VERSION ""

NS_ :

BS_:
BU_: POD STARC VCU

BO_ 5 HEARTBEAT_VCU: 1 VCU
  SG_ HEARTBEAT_CMD : 0|8@0- (1,0) [0|255] "" POD

BO_ 109 FRONT_STEER_CMD: 8 POD,STARC
  SG_ FRONT_STEER_ANGLE : 0|16@0- (1,0) [-150|150] "degrees" VCU
  SG_ REAR_STEER_ANGLE : 16|16@0- (1,0) [-150|150] "degrees" VCU
  SG_ STEER_RATE : 32|8@0+ (1,0) [-128|128] "rad/s" VCU
  SG_ CTRL_REQUEST : 40|4@0- (1,0) [0|8] "" VCU
  SG_ CTRL_PRIORITY : 44|4@0- (1,0) [0|8] "" VCU

BO_ 110 STEERING_STATUS: 8 VCU
  SG_ FRONT_STEER_ANGLE : 0|16@0- (1,0) [-150|150] "degrees" POD,STARC
  SG_ REAR_STEER_ANGLE : 16|16@0- (1,0) [-150|150] "degrees" POD,STARC
  SG_ MOTOR_TEMP : 32|8@0- (1,0) [0|110] "celcius" POD,STARC
  SG_ MOTOR_CURRENT : 40|8@0- (1,0) [0|100] "Amperes" POD,STARC
  SG_ STEER_ANGLE_ERROR : 48|8@0- (1,0) [-150|150] "degrees" POD,STARC
  SG_ STEER_ANGLE_STATUS : 56|4@0- (1,0) [0|8] "" POD,STARC

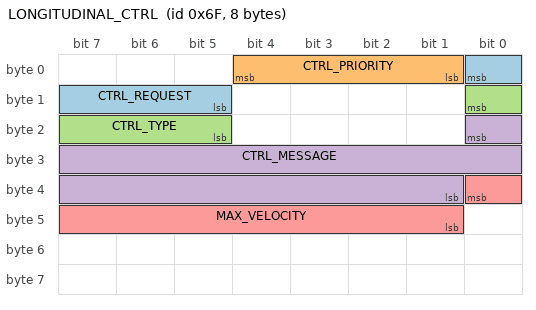
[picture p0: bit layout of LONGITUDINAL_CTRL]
BO_ 111 LONGITUDINAL_CTRL: 8 POD,STARC
  SG_ CTRL_REQUEST : 0|4@0- (1,0) [0|8] "" VCU
  SG_ CTRL_PRIORITY : 4|4@0- (1,0) [0|8] "" VCU
  SG_ CTRL_TYPE : 8|4@0- (1,0) [0|8] "" VCU
  SG_ CTRL_MESSAGE : 16|16@0- (1,0) [0|65536] "" VCU
  SG_ MAX_VELOCITY : 32|8@0- (1,0) [0|255] "" VCU

BO_ 112 TORQUE_VECTORS: 8 POD
  SG_ F_L_CTRL_MSG : 0|16@0- (1,0) [0|65536] "" VCU
  SG_ R_L_CTRL_MSG : 16|16@0- (1,0) [0|65536] "" VCU
  SG_ F_R_CTRL_MSG : 32|16@0- (1,0) [0|65536] "" VCU
  SG_ R_R_CTRL_MSG : 48|16@0- (1,0) [0|65536] "" VCU

BO_ 113 LONGITUDIANL STATUS: 8 VCU
  SG_ WHEEL_POS_CTR : 0|12@0- (1,0) [0|4096] "" VCU
  SG_ WHEEL_VELOCITY : 12|10@0+ (1,0) [-512|512] "rad/s" VCU
  SG_ STATOR_TEMP : 22|8@0- (1,0) [0|110] "celcius" VCU
  SG_ MOTOR_VOL : 30|8@0- (1,0) [0|60] "volts" VCU
  SG_ MOTOR_CURRENT : 38|8@0- [0|110] "amperes VCU
  SG_ MOTOR_TORQUE : 46|10@0- [0|1024] "n.m" VCU
  SG_ CTRL_STATE : 56|4@0- [0|8] "" VCU




CM_ BU_ POD "AEV Pod Module";
CM_ BU_ STARC "AEV STARc Module";
CM_ BU_ VCU "AEV VCU Module";
CM_ BO_ 100 "Sync message for controllers.";

VAL_ 109 CTRL_REQUEST 0 "No Control" 2 "Request Control" 4 "Control" 8 "Release Control";
VAL_ 109 CTRL_PRIORITY 0 "No Control Input" 2 "Low Priority" 4 "High Priority" 8 "No device can take over";
VAL_ 110 STEER_ANGLE_STATUS 0 "Unable to achieve target" 2 " Over Current" 4 "Over Temperature" 8 "Communication Error" 16 "Future Error Msgs TBD";
VAL_ 111 CTRL_REQUEST 0 "No Control" 2 "Request Control" 4 "Control" 8 "Release Control";
VAL_ 111 CTRL_PRIORITY 0 "No Control Input" 2 "Low Priority" 4 "High Priority" 8 "No device can take over";
VAL_ 111 CTRL_TYPE 0 "Power Control" 2 "Velocity Control" 4 " POD Individual Wheel Control";
VAL_ 113 CTRL_STATE 0 "Unable to achieve target" 2 " Over Current" 4 "Over Temperature" 8 "Communication Error" 16 "Future Errror Msgs TBD";
